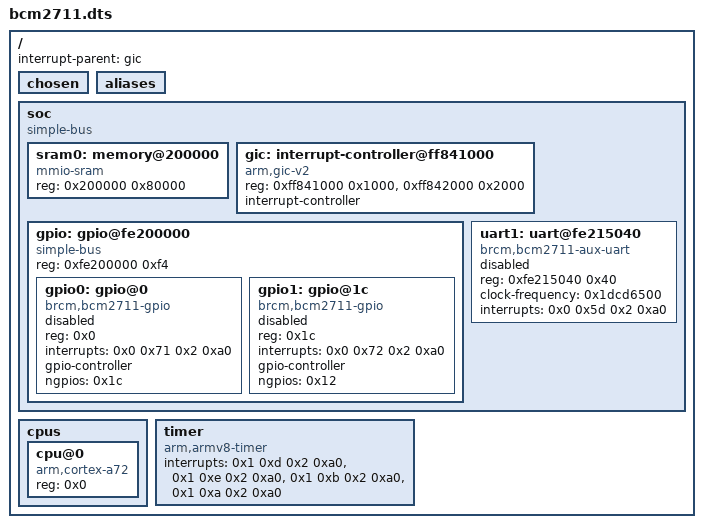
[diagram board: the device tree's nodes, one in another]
/dts-v1/;

/ {
	#address-cells = < 0x1 >;
	#size-cells = < 0x1 >;
	interrupt-parent = < &gic >;
	chosen {
	};
	aliases {
	};
	soc {
		#address-cells = < 0x1 >;
		#size-cells = < 0x1 >;
		compatible = "simple-bus";
		ranges;
		sram0: memory@200000 {
			device_type = "memory";
			compatible = "mmio-sram";
			reg = < 0x200000 0x80000 >;
		};
		gic: interrupt-controller@ff841000 {
			compatible = "arm,gic-v2", "arm,gic";
			reg = < 0xff841000 0x1000 >, < 0xff842000 0x2000 >;
			interrupt-controller;
			#interrupt-cells = < 0x4 >;
			status = "okay";
			phandle = < 0x1 >;
		};
		gpio: gpio@fe200000 {
			compatible = "simple-bus";
			reg = < 0xfe200000 0xf4 >;
			#address-cells = < 0x1 >;
			#size-cells = < 0x0 >;
			gpio0: gpio@0 {
				compatible = "brcm,bcm2711-gpio";
				reg = < 0x0 >;
				interrupts = < 0x0 0x71 0x2 0xa0 >;
				gpio-controller;
				#gpio-cells = < 0x2 >;
				ngpios = < 0x1c >;
				status = "disabled";
			};
			gpio1: gpio@1c {
				compatible = "brcm,bcm2711-gpio";
				reg = < 0x1c >;
				interrupts = < 0x0 0x72 0x2 0xa0 >;
				gpio-controller;
				#gpio-cells = < 0x2 >;
				ngpios = < 0x12 >;
				status = "disabled";
			};
		};
		uart1: uart@fe215040 {
			compatible = "brcm,bcm2711-aux-uart";
			reg = < 0xfe215040 0x40 >;
			clock-frequency = < 0x1dcd6500 >;
			interrupts = < 0x0 0x5d 0x2 0xa0 >;
			status = "disabled";
		};
	};
	cpus {
		#address-cells = < 0x1 >;
		#size-cells = < 0x0 >;
		cpu@0 {
			device_type = "cpu";
			compatible = "arm,cortex-a72";
			reg = < 0x0 >;
		};
	};
	timer {
		compatible = "arm,armv8-timer";
		interrupts = < 0x1 0xd 0x2 0xa0 >, < 0x1 0xe 0x2 0xa0 >, < 0x1 0xb 0x2 0xa0 >, < 0x1 0xa 0x2 0xa0 >;
	};
};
